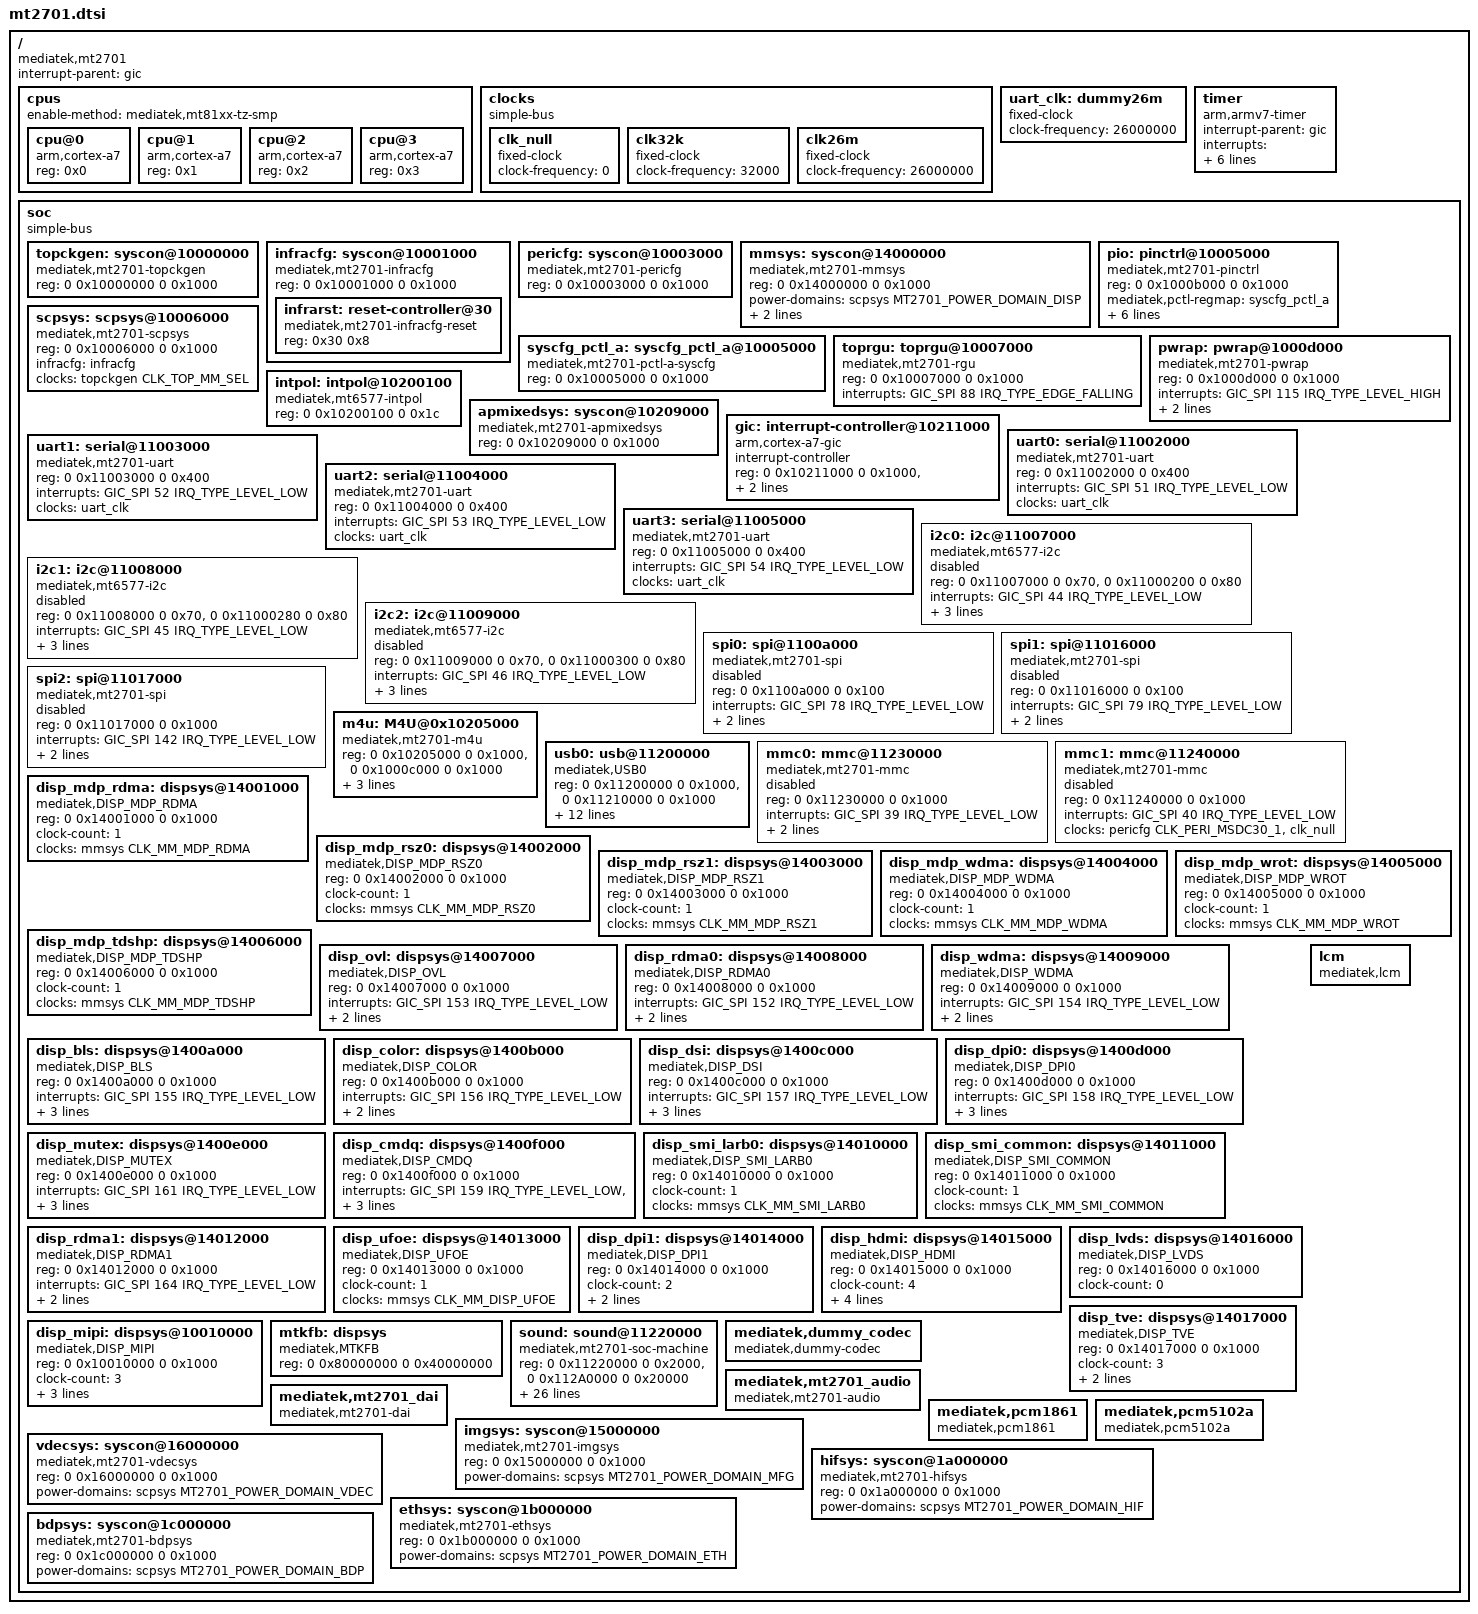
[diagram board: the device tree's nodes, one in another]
/*
 * Copyright (c) 2015 MediaTek Inc.
 * Author: Erin.Lo <erin.lo@mediatek.com>
 *
 * This program is free software; you can redistribute it and/or modify
 * it under the terms of the GNU General Public License version 2 as
 * published by the Free Software Foundation.
 *
 * This program is distributed in the hope that it will be useful,
 * but WITHOUT ANY WARRANTY; without even the implied warranty of
 * MERCHANTABILITY or FITNESS FOR A PARTICULAR PURPOSE.  See the
 * GNU General Public License for more details.
 */

#include <dt-bindings/interrupt-controller/irq.h>
#include <dt-bindings/interrupt-controller/arm-gic.h>
#include <dt-bindings/clock/mt2701-clk.h>
#include <dt-bindings/power/mt2701-power.h>
#include "skeleton64.dtsi"
#include "mt2701-pinfunc.h"

/ {
	compatible = "mediatek,mt2701";
	interrupt-parent = <&gic>;

	cpus {
		#address-cells = <1>;
		#size-cells = <0>;
		enable-method = "mediatek,mt81xx-tz-smp";

		cpu@0 {
			device_type = "cpu";
			compatible = "arm,cortex-a7";
			reg = <0x0>;
		};
		cpu@1 {
			device_type = "cpu";
			compatible = "arm,cortex-a7";
			reg = <0x1>;
		};
		cpu@2 {
			device_type = "cpu";
			compatible = "arm,cortex-a7";
			reg = <0x2>;
		};
		cpu@3 {
			device_type = "cpu";
			compatible = "arm,cortex-a7";
			reg = <0x3>;
		};
	};

	clocks {
		#address-cells = <2>;
		#size-cells = <2>;
		compatible = "simple-bus";
		ranges;

		clk_null: clk_null {
			compatible = "fixed-clock";
			#clock-cells = <0>;
			clock-frequency = <0>;
		};

		clk32k: clk32k {
			compatible = "fixed-clock";
			clock-frequency = <32000>;
			#clock-cells = <0>;
		};

		clk26m: clk26m {
			compatible = "fixed-clock";
			clock-frequency = <26000000>;
			#clock-cells = <0>;
		};
	};

	uart_clk: dummy26m {
		compatible = "fixed-clock";
		clock-frequency = <26000000>;
		#clock-cells = <0>;
	};

	timer {
		compatible = "arm,armv7-timer";
		interrupt-parent = <&gic>;
		interrupts = <GIC_PPI 13 (GIC_CPU_MASK_SIMPLE(4) | IRQ_TYPE_LEVEL_HIGH)>,
			     <GIC_PPI 14 (GIC_CPU_MASK_SIMPLE(4) | IRQ_TYPE_LEVEL_HIGH)>,
			     <GIC_PPI 11 (GIC_CPU_MASK_SIMPLE(4) | IRQ_TYPE_LEVEL_HIGH)>,
			     <GIC_PPI 10 (GIC_CPU_MASK_SIMPLE(4) | IRQ_TYPE_LEVEL_HIGH)>;
		clock-frequency = <13000000>;
		arm,cpu-registers-not-fw-configured;
	};

	soc {
		#address-cells = <2>;
		#size-cells = <2>;
		compatible = "simple-bus";
		ranges;

		topckgen: syscon@10000000 {
			compatible = "mediatek,mt2701-topckgen", "syscon";
			reg = <0 0x10000000 0 0x1000>;
			#clock-cells = <1>;
		};

		infracfg: syscon@10001000 {
			#address-cells = <1>;
			#size-cells = <1>;
			compatible = "mediatek,mt2701-infracfg", "syscon";
			reg = <0 0x10001000 0 0x1000>;
			#clock-cells = <1>;

			infrarst: reset-controller@30 {
				#reset-cells = <1>;
				compatible = "mediatek,mt2701-infracfg-reset", "mediatek,reset";
				reg = <0x30 0x8>;
			};
		};

		pericfg: syscon@10003000 {
			#address-cells = <1>;
			#size-cells = <1>;
			compatible = "mediatek,mt2701-pericfg", "syscon";
			reg = <0 0x10003000 0 0x1000>;
			#clock-cells = <1>;
		};

		mmsys: syscon@14000000 {
			#address-cells = <1>;
			#size-cells = <1>;
			compatible = "mediatek,mt2701-mmsys", "syscon", "mediatek,DISP_CONFIG";
			reg = <0 0x14000000 0 0x1000>;
			#clock-cells = <1>;
			power-domains = <&scpsys MT2701_POWER_DOMAIN_DISP>;
			clock-count = <1>;
			clocks = <&topckgen CLK_TOP_MM_SEL>;
			clock-names = "CLK_TOP_MM_SEL";
		};

		pio: pinctrl@10005000 {
			compatible = "mediatek,mt2701-pinctrl";
			reg = <0 0x1000b000 0 0x1000>;
			mediatek,pctl-regmap = <&syscfg_pctl_a>;
			pins-are-numbered;
			gpio-controller;
			#gpio-cells = <2>;
			interrupt-controller;
			#interrupt-cells = <2>;
			interrupts = <GIC_SPI 113 IRQ_TYPE_LEVEL_HIGH>,
					<GIC_SPI 114 IRQ_TYPE_LEVEL_HIGH>,
					<GIC_SPI 115  IRQ_TYPE_LEVEL_HIGH>;
		};

		syscfg_pctl_a: syscfg_pctl_a@10005000 {
			compatible = "mediatek,mt2701-pctl-a-syscfg", "syscon";
			reg = <0 0x10005000 0 0x1000>;
		};

		scpsys: scpsys@10006000 {
			compatible = "mediatek,mt2701-scpsys", "syscon";
			#power-domain-cells = <1>;
			reg = <0 0x10006000 0 0x1000>;
			infracfg = <&infracfg>;
			clocks = <&topckgen CLK_TOP_MM_SEL>;
			clock-names = "mm";
		};

		toprgu: toprgu@10007000 {
			compatible = "mediatek,mt2701-rgu";
			reg = <0 0x10007000 0 0x1000>;
			interrupts = <GIC_SPI 88 IRQ_TYPE_EDGE_FALLING>;
		};

		pwrap: pwrap@1000d000 {
			compatible = "mediatek,mt2701-pwrap";
			reg = <0 0x1000d000 0 0x1000>;
			reg-names = "pwrap-base";
			interrupts = <GIC_SPI 115 IRQ_TYPE_LEVEL_HIGH>;
			clocks = <&infracfg CLK_INFRA_PMICSPI>, <&infracfg CLK_INFRA_PMICWRAP> ;
			clock-names = "pmicspi-clk", "pmicwrap-clk";
		};

		intpol: intpol@10200100 {
			compatible = "mediatek,mt6577-intpol";
			reg = <0 0x10200100 0 0x1c>;
		};

		apmixedsys: syscon@10209000 {
			compatible = "mediatek,mt2701-apmixedsys", "syscon";
			reg = <0 0x10209000 0 0x1000>;
			#clock-cells = <1>;
		};

		gic: interrupt-controller@10211000 {
			compatible = "arm,cortex-a7-gic";
			interrupt-controller;
			#interrupt-cells = <3>;
			reg = <0 0x10211000 0 0x1000>,
			      <0 0x10212000 0 0x1000>,
			      <0 0x10214000 0 0x2000>,
			      <0 0x10216000 0 0x2000>;
		};

		uart0: serial@11002000 {
			compatible = "mediatek,mt2701-uart","mediatek,mt6577-uart";
			reg = <0 0x11002000 0 0x400>;
			interrupts = <GIC_SPI 51 IRQ_TYPE_LEVEL_LOW>;
			clocks = <&uart_clk>;
		};

		uart1: serial@11003000 {
			compatible = "mediatek,mt2701-uart","mediatek,mt6577-uart";
			reg = <0 0x11003000 0 0x400>;
			interrupts = <GIC_SPI 52 IRQ_TYPE_LEVEL_LOW>;
			clocks = <&uart_clk>;
		};

		uart2: serial@11004000 {
			compatible = "mediatek,mt2701-uart","mediatek,mt6577-uart";
			reg = <0 0x11004000 0 0x400>;
			interrupts = <GIC_SPI 53 IRQ_TYPE_LEVEL_LOW>;
			clocks = <&uart_clk>;
		};

		uart3: serial@11005000 {
			compatible = "mediatek,mt2701-uart","mediatek,mt6577-uart";
			reg = <0 0x11005000 0 0x400>;
			interrupts = <GIC_SPI 54 IRQ_TYPE_LEVEL_LOW>;
			clocks = <&uart_clk>;
		};

		i2c0: i2c@11007000 {
			compatible = "mediatek,mt6577-i2c";
			reg = <0 0x11007000 0 0x70>,
			      <0 0x11000200 0 0x80>;
			interrupts = <GIC_SPI 44 IRQ_TYPE_LEVEL_LOW>;
			clock-div = <16>;
			clocks = <&pericfg CLK_PERI_I2C0>, <&pericfg CLK_PERI_AP_DMA>;
			clock-names = "main", "dma";
			status = "disabled";
		};

		i2c1: i2c@11008000 {
			compatible = "mediatek,mt6577-i2c";
			reg = <0 0x11008000 0 0x70>,
			      <0 0x11000280 0 0x80>;
			interrupts = <GIC_SPI 45 IRQ_TYPE_LEVEL_LOW>;
			clock-div = <16>;
			clocks = <&pericfg CLK_PERI_I2C1>, <&pericfg CLK_PERI_AP_DMA>;
			clock-names = "main", "dma";
			status = "disabled";
		};

		i2c2: i2c@11009000 {
			compatible = "mediatek,mt6577-i2c";
			reg = <0 0x11009000 0 0x70>,
			      <0 0x11000300 0 0x80>;
			interrupts = <GIC_SPI 46 IRQ_TYPE_LEVEL_LOW>;
			clock-div = <16>;
			clocks = <&pericfg CLK_PERI_I2C2>, <&pericfg CLK_PERI_AP_DMA>;
			clock-names = "main", "dma";
			status = "disabled";
		};

		spi0: spi@1100a000 {
			compatible = "mediatek,mt2701-spi";
			reg = <0 0x1100a000 0 0x100>;
			interrupts = <GIC_SPI 78 IRQ_TYPE_LEVEL_LOW>;
			clocks = <&pericfg CLK_PERI_SPI0>;
			clock-names = "main";
			cell-index = <0>;
			#address-cells = <0x1>;
			#size-cells = <0>;
			status = "disabled";
		};

		spi1: spi@11016000 {
			compatible = "mediatek,mt2701-spi";
			reg = <0 0x11016000 0 0x100>;
			interrupts = <GIC_SPI 79 IRQ_TYPE_LEVEL_LOW>;
			clocks = <&pericfg CLK_PERI_SPI1>;
			clock-names = "main";
			cell-index = <1>;
			#address-cells = <0x1>;
			#size-cells = <0>;
			status = "disabled";
		};

		spi2: spi@11017000 {
			compatible = "mediatek,mt2701-spi";
			reg = <0 0x11017000 0 0x1000>;
			interrupts = <GIC_SPI 142 IRQ_TYPE_LEVEL_LOW>;
			clocks = <&pericfg CLK_PERI_SPI2>;
			clock-names = "main";
			cell-index = <2>;
			#address-cells = <0x1>;
			#size-cells = <0>;
			status = "disabled";
		};

		m4u: M4U@0x10205000 {
			compatible = "mediatek,mt2701-m4u";
			reg = <0 0x10205000 0 0x1000>,
				<0 0x1000c000 0 0x1000>; /* SMI COMMON AO */
			interrupts = <GIC_SPI 106 IRQ_TYPE_LEVEL_LOW>;
			clocks = <&infracfg CLK_INFRA_M4U>,
					<&infracfg CLK_INFRA_SMI>;
			clock-names = "infra_m4u", "infra_smi";
		};

		usb0: usb@11200000 {
			compatible = "mediatek,USB0";
			reg = <0 0x11200000 0 0x1000>,
			      <0 0x11210000 0 0x1000>;
			interrupts = <GIC_SPI 32 IRQ_TYPE_LEVEL_LOW>;
			mode = <2>;
			multipoint = <1>;
			dyn_fifo = <1>;
			soft_con = <1>;
			dma = <1>;
			num_eps = <16>;
			dma_channels = <8>;
			clocks = <&pericfg CLK_PERI_USB0>,
				 <&pericfg CLK_PERI_USB0_MCU>,
				 <&pericfg CLK_PERI_USB_SLV>;
			clock-names = "usb0_main","usb0_mcu","usb_slv";
			usb-power-supply = <&mt6323_vusb_reg>;
		};

		mmc0: mmc@11230000 {
			compatible = "mediatek,mt2701-mmc";
			reg = <0 0x11230000 0 0x1000>;
			interrupts = <GIC_SPI 39 IRQ_TYPE_LEVEL_LOW>;
			clocks = <&pericfg CLK_PERI_MSDC30_0>,
				 <&topckgen CLK_PERI_MSDC50_3>;
			clock-names = "source", "hclk";
			status = "disabled";
		};

		mmc1: mmc@11240000 {
			compatible = "mediatek,mt2701-mmc";
			reg = <0 0x11240000 0 0x1000>;
			interrupts = <GIC_SPI 40 IRQ_TYPE_LEVEL_LOW>;
			clocks = <&pericfg CLK_PERI_MSDC30_1>,
				 <&clk_null>;
			clock-names = "source", "hclk";
			status = "disabled";
		};

		disp_mdp_rdma: dispsys@14001000 {
			compatible = "mediatek,DISP_MDP_RDMA";
			reg = <0 0x14001000 0 0x1000>;
			clock-count = <1>;
			clocks = <&mmsys CLK_MM_MDP_RDMA>;
			clock-names = "CLK_MM_MDP_RDMA";
		};

		disp_mdp_rsz0: dispsys@14002000 {
			compatible = "mediatek,DISP_MDP_RSZ0";
			reg = <0 0x14002000 0 0x1000>;
			clock-count = <1>;
			clocks = <&mmsys CLK_MM_MDP_RSZ0>;
			clock-names = "CLK_MM_MDP_RSZ0";
		};

		disp_mdp_rsz1: dispsys@14003000 {
			compatible = "mediatek,DISP_MDP_RSZ1";
			reg = <0 0x14003000 0 0x1000>;
			clock-count = <1>;
			clocks = <&mmsys CLK_MM_MDP_RSZ1>;
			clock-names = "CLK_MM_MDP_RSZ1";
		};

		disp_mdp_wdma: dispsys@14004000 {
			compatible = "mediatek,DISP_MDP_WDMA";
			reg = <0 0x14004000 0 0x1000>;
			clock-count = <1>;
			clocks = <&mmsys CLK_MM_MDP_WDMA>;
			clock-names = "CLK_MM_MDP_WDMA";
		};

		disp_mdp_wrot: dispsys@14005000 {
			compatible = "mediatek,DISP_MDP_WROT";
			reg = <0 0x14005000 0 0x1000>;
			clock-count = <1>;
			clocks = <&mmsys CLK_MM_MDP_WROT>;
			clock-names = "CLK_MM_MDP_WROT";
		};

		disp_mdp_tdshp: dispsys@14006000 {
			compatible = "mediatek,DISP_MDP_TDSHP";
			reg = <0 0x14006000 0 0x1000>;
			clock-count = <1>;
			clocks = <&mmsys CLK_MM_MDP_TDSHP>;
			clock-names = "CLK_MM_MDP_TDSHP";
		};

		disp_ovl: dispsys@14007000 {
			compatible = "mediatek,DISP_OVL";
			reg = <0 0x14007000 0 0x1000>;
			interrupts = <GIC_SPI 153 IRQ_TYPE_LEVEL_LOW>;
			clock-count = <1>;
			clocks = <&mmsys CLK_MM_DISP_OVL>;
			clock-names = "CLK_MM_DISP_OVL";
		};

		disp_rdma0: dispsys@14008000 {
			compatible = "mediatek,DISP_RDMA0";
			reg = <0 0x14008000 0 0x1000>;
			interrupts = <GIC_SPI 152 IRQ_TYPE_LEVEL_LOW>;
			clock-count = <1>;
			clocks = <&mmsys CLK_MM_DISP_RDMA>;
			clock-names = "CLK_MM_DISP_RDMA";
		};

		disp_wdma: dispsys@14009000 {
			compatible = "mediatek,DISP_WDMA";
			reg = <0 0x14009000 0 0x1000>;
			interrupts = <GIC_SPI 154 IRQ_TYPE_LEVEL_LOW>;
			clock-count = <1>;
			clocks = <&mmsys CLK_MM_DISP_WDMA>;
			clock-names = "CLK_MM_DISP_WDMA";
		};

		disp_bls: dispsys@1400a000 {
			compatible = "mediatek,DISP_BLS";
			reg = <0 0x1400a000 0 0x1000>;
			interrupts = <GIC_SPI 155 IRQ_TYPE_LEVEL_LOW>;
			clock-count = <2>;
			clocks = <&mmsys CLK_MM_DISP_BLS>,
					 <&mmsys CLK_MM_MDP_BLS_26M>;
			clock-names = "CLK_MM_DISP_BLS",
						  "CLK_MM_MDP_BLS_26M";
		};

		disp_color: dispsys@1400b000 {
			compatible = "mediatek,DISP_COLOR";
			reg = <0 0x1400b000 0 0x1000>;
			interrupts = <GIC_SPI 156 IRQ_TYPE_LEVEL_LOW>;
			clock-count = <1>;
			clocks = <&mmsys CLK_MM_DISP_COLOR>;
			clock-names = "CLK_MM_DISP_COLOR";
		};

		disp_dsi: dispsys@1400c000 {
			compatible = "mediatek,DISP_DSI";
			reg = <0 0x1400c000 0 0x1000>;
			interrupts = <GIC_SPI 157 IRQ_TYPE_LEVEL_LOW>;
			clock-count = <2>;
			clocks = <&mmsys CLK_MM_DSI_ENGINE>,
					 <&mmsys CLK_MM_DSI_DIG>;
			clock-names = "CLK_MM_DSI_ENGINE",
						  "CLK_MM_DSI_DIG";
		};

		disp_dpi0: dispsys@1400d000 {
			compatible = "mediatek,DISP_DPI0";
			reg = <0 0x1400d000 0 0x1000>;
			interrupts = <GIC_SPI 158 IRQ_TYPE_LEVEL_LOW>;
			clock-count = <2>;
			clocks = <&mmsys CLK_MM_DPI_DIGL>,
					 <&mmsys CLK_MM_DPI_ENGINE>;
			clock-names = "CLK_MM_DPI_DIGL",
						  "CLK_MM_DPI_ENGINE";
		};

		disp_mutex: dispsys@1400e000 {
			compatible = "mediatek,DISP_MUTEX";
			reg = <0 0x1400e000 0 0x1000>;
			interrupts = <GIC_SPI 161 IRQ_TYPE_LEVEL_LOW>;
			clock-count = <2>;
			clocks = <&mmsys CLK_MM_MUTEX_32K>,
					 <&mmsys CLK_MM_MUTEX>;
			clock-names = "CLK_MM_MUTEX_32K",
						  "CLK_MM_MUTEX";
		};

		disp_cmdq: dispsys@1400f000 {
			compatible = "mediatek,DISP_CMDQ";
			reg = <0 0x1400f000 0 0x1000>;
			interrupts = <GIC_SPI 159 IRQ_TYPE_LEVEL_LOW>,
						<GIC_SPI 160 IRQ_TYPE_LEVEL_LOW>;
			clock-count = <1>;
			clocks = <&mmsys CLK_MM_CMDQ>;
			clock-names = "CLK_MM_CMDQ";
		};

		disp_smi_larb0: dispsys@14010000 {
			compatible = "mediatek,DISP_SMI_LARB0";
			reg = <0 0x14010000 0 0x1000>;
			clock-count = <1>;
			clocks = <&mmsys CLK_MM_SMI_LARB0>;
			clock-names = "CLK_MM_SMI_LARB0";
		};

		disp_smi_common: dispsys@14011000 {
			compatible = "mediatek,DISP_SMI_COMMON";
			reg = <0 0x14011000 0 0x1000>;
			clock-count = <1>;
			clocks = <&mmsys CLK_MM_SMI_COMMON>;
			clock-names = "CLK_MM_SMI_COMMON";
		};

		disp_rdma1: dispsys@14012000 {
			compatible = "mediatek,DISP_RDMA1";
			reg = <0 0x14012000 0 0x1000>;
			interrupts = <GIC_SPI 164 IRQ_TYPE_LEVEL_LOW>;
			clock-count = <1>;
			clocks = <&mmsys CLK_MM_DISP_RDMA1>;
			clock-names = "CLK_MM_DISP_RDMA1";
		};

		disp_ufoe: dispsys@14013000 {
			compatible = "mediatek,DISP_UFOE";
			reg = <0 0x14013000 0 0x1000>;
			clock-count = <1>;
			clocks = <&mmsys CLK_MM_DISP_UFOE>;
			clock-names = "CLK_MM_DISP_UFOE";
		};

		disp_dpi1: dispsys@14014000 {
			compatible = "mediatek,DISP_DPI1";
			reg = <0 0x14014000 0 0x1000>;
			clock-count = <2>;
			clocks = <&mmsys CLK_MM_DPI1_DIGL>,
					 <&mmsys CLK_MM_DPI1_ENGINE>;
			clock-names = "CLK_MM_DPI1_DIGL",
						  "CLK_MM_DPI1_ENGINE";
		};

		disp_hdmi: dispsys@14015000 {
			compatible = "mediatek,DISP_HDMI";
			reg = <0 0x14015000 0 0x1000>;
			clock-count = <4>;
			clocks = <&mmsys CLK_MM_HDMI_PIXEL>,
					 <&mmsys CLK_MM_HDMI_PLL>,
					 <&mmsys CLK_MM_HDMI_AUDIO>,
					 <&mmsys CLK_MM_HDMI_SPDIF>;
			clock-names = "CLK_MM_HDMI_PIXEL",
						  "CLK_MM_HDMI_PLL",
						  "CLK_MM_HDMI_AUDIO",
						  "CLK_MM_HDMI_SPDIF";
		};

		disp_lvds: dispsys@14016000 {
			compatible = "mediatek,DISP_LVDS";
			reg = <0 0x14016000 0 0x1000>;
			clock-count = <0>;
		};

		disp_tve: dispsys@14017000 {
			compatible = "mediatek,DISP_TVE";
			reg = <0 0x14017000 0 0x1000>;
			clock-count = <3>;
			clocks = <&mmsys CLK_MM_TVE_OUTPUT>,
					 <&mmsys CLK_MM_TVE_INPUT>,
					 <&mmsys CLK_MM_TVE_FMM>;
			clock-names = "CLK_MM_TVE_OUTPUT",
						  "CLK_MM_TVE_INPUT",
						  "CLK_MM_TVE_FMM";
		};

		disp_mipi: dispsys@10010000 {
			compatible = "mediatek,DISP_MIPI";
			reg = <0 0x10010000 0 0x1000>;
			clock-count = <3>;
			clocks = <&topckgen CLK_TOP_MIPIPLL>,
					 <&topckgen CLK_TOP_MIPIPLL_D2>,
					 <&topckgen CLK_TOP_MIPIPLL_D4>;
			clock-names = "CLK_TOP_MIPIPLL",
						  "CLK_TOP_MIPIPLL_D2",
						  "CLK_TOP_MIPIPLL_D4";
		};

		mtkfb: dispsys {
			compatible = "mediatek,MTKFB";
			reg = <0 0x80000000 0 0x40000000>;
		};

		lcm: lcm {
			compatible = "mediatek,lcm";
		};

		sound:sound@11220000 {
			compatible = "mediatek,mt2701-soc-machine";
			#address-cells = <2>;
			#size-cells = <2>;
			 reg = <0 0x11220000 0 0x2000>,
			       <0 0x112A0000 0 0x20000>;
			interrupts = <GIC_SPI 104 IRQ_TYPE_LEVEL_LOW>,
				     <GIC_SPI 132 IRQ_TYPE_LEVEL_LOW>;

			clocks = <&infracfg CLK_INFRA_AUDIO>,
				 <&topckgen CLK_TOP_AUD_MUX1_SEL>,
				 <&topckgen CLK_TOP_AUD_MUX2_SEL>,
				 <&topckgen CLK_TOP_AUDPLL_MUX_SEL>,
				 <&topckgen CLK_TOP_APLL_SEL>,
				 <&topckgen CLK_TOP_AUD1PLL_98M>,
				 <&topckgen CLK_TOP_AUD2PLL_90M>,
				 <&topckgen CLK_TOP_HADDS2PLL_98M>,
				 <&topckgen CLK_TOP_HADDS2PLL_294M>,
				 <&topckgen CLK_TOP_AUDPLL>,
				 <&topckgen CLK_TOP_AUDPLL_D4>,
				 <&topckgen CLK_TOP_AUDPLL_D8>,
				 <&topckgen CLK_TOP_AUDPLL_D16>,
				 <&topckgen CLK_TOP_AUDPLL_D24>,
				 <&topckgen CLK_TOP_AUDINTBUS_SEL>,
				 <&clk26m>,
				 <&topckgen CLK_TOP_SYSPLL1_D4>,
				 <&topckgen CLK_TOP_AUD_K1_SRC_SEL>,
				 <&topckgen CLK_TOP_AUD_K2_SRC_SEL>,
				 <&topckgen CLK_TOP_AUD_K3_SRC_SEL>,
				 <&topckgen CLK_TOP_AUD_K4_SRC_SEL>,
				 <&topckgen CLK_TOP_AUD_K1_SRC_DIV>,
				 <&topckgen CLK_TOP_AUD_K2_SRC_DIV>,
				 <&topckgen CLK_TOP_AUD_K3_SRC_DIV>,
				 <&topckgen CLK_TOP_AUD_K4_SRC_DIV>;


			clock-names = "infra_sys_audio_clk",
				      "top_audio_mux1_sel",
				      "top_audio_mux2_sel",
				      "top_audpll_mux_sel",
				      "top_apll_sel",
				      "top_aud1_pll_98M",
				      "top_aud2_pll_90M",
				      "top_hadds2_pll_98M",
				      "top_hadds2_pll_294M",
				      "top_audpll",
				      "top_audpll_d4",
				      "top_audpll_d8",
				      "top_audpll_d16",
				      "top_audpll_d24",
				      "top_audintbus_sel",
				      "clk_26m",
				      "top_syspll1_d4",
				      "top_aud_k1_src_sel",
				      "top_aud_k2_src_sel",
				      "top_aud_k3_src_sel",
				      "top_aud_k4_src_sel",
				      "top_aud_k1_src_div",
				      "top_aud_k2_src_div",
				      "top_aud_k3_src_div",
				      "top_aud_k4_src_div";
		};

		mediatek,dummy_codec {
			compatible = "mediatek,dummy-codec";
		};

		mediatek,mt2701_audio {
			compatible = "mediatek,mt2701-audio";
		};

		mediatek,mt2701_dai {
			compatible = "mediatek,mt2701-dai";
		};

		mediatek,pcm1861 {
			compatible = "mediatek,pcm1861";
		};

		mediatek,pcm5102a {
			compatible = "mediatek,pcm5102a";
		};

		imgsys: syscon@15000000 {
			#address-cells = <1>;
			#size-cells = <1>;
			compatible = "mediatek,mt2701-imgsys", "syscon";
			reg = <0 0x15000000 0 0x1000>;
			#clock-cells = <1>;
			power-domains = <&scpsys MT2701_POWER_DOMAIN_MFG>;
		};

		vdecsys: syscon@16000000 {
			#address-cells = <1>;
			#size-cells = <1>;
			compatible = "mediatek,mt2701-vdecsys", "syscon";
			reg = <0 0x16000000 0 0x1000>;
			#clock-cells = <1>;
			power-domains = <&scpsys MT2701_POWER_DOMAIN_VDEC>;
		};

		hifsys: syscon@1a000000 {
			#address-cells = <1>;
			#size-cells = <1>;
			compatible = "mediatek,mt2701-hifsys", "syscon";
			reg = <0 0x1a000000 0 0x1000>;
			#clock-cells = <1>;
			power-domains = <&scpsys MT2701_POWER_DOMAIN_HIF>;
		};

		ethsys: syscon@1b000000 {
			#address-cells = <1>;
			#size-cells = <1>;
			compatible = "mediatek,mt2701-ethsys", "syscon";
			reg = <0 0x1b000000 0 0x1000>;
			#clock-cells = <1>;
			power-domains = <&scpsys MT2701_POWER_DOMAIN_ETH>;
		};

		bdpsys: syscon@1c000000 {
			#address-cells = <1>;
			#size-cells = <1>;
			compatible = "mediatek,mt2701-bdpsys", "syscon";
			reg = <0 0x1c000000 0 0x1000>;
			#clock-cells = <1>;
			power-domains = <&scpsys MT2701_POWER_DOMAIN_BDP>;
		};

	};
};
